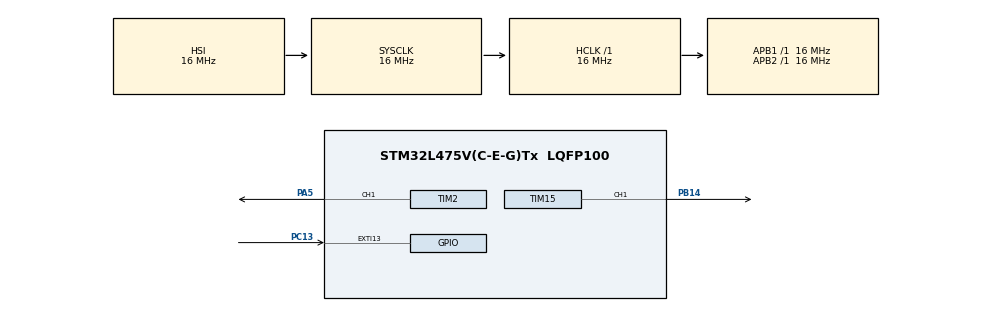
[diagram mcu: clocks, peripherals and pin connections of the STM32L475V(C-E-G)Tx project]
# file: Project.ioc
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Mcu.Family=STM32L4
Mcu.Name=STM32L475V(C-E-G)Tx
Mcu.Package=LQFP100
NVIC.EXTI15_10_IRQn=true\:0\:0\:false\:false\:true\:true\:true
NVIC.PriorityGroup=NVIC_PRIORITYGROUP_4
PA5.Signal=S_TIM2_CH1
PB14.Signal=S_TIM15_CH1
PC13.Signal=GPXTI13
ProjectManager.HeapSize=0x200
ProjectManager.StackSize=0x400
ProjectManager.TargetToolchain=EWARM V8.32
RCC.AHBFreq_Value=16000000
RCC.APB1Freq_Value=16000000
RCC.APB1TimFreq_Value=16000000
RCC.APB2Freq_Value=16000000
RCC.APB2TimFreq_Value=16000000
RCC.CortexFreq_Value=16000000
RCC.HCLKFreq_Value=16000000
RCC.HSE_VALUE=8000000
RCC.HSI_VALUE=16000000
RCC.LSE_VALUE=32768
RCC.MSI_VALUE=4000000
RCC.SYSCLKFreq_VALUE=16000000
RCC.SYSCLKSource=RCC_SYSCLKSOURCE_HSI
RCC.VCOOutputFreq_Value=32000000
SH.S_TIM15_CH1.0=TIM15_CH1,PWM Generation1 CH1
SH.S_TIM2_CH1.0=TIM2_CH1,PWM Generation1 CH1
TIM15.Channel-PWM\ Generation1\ CH1=TIM_CHANNEL_1
TIM15.Period=2000-1
TIM15.Prescaler=160-1
TIM2.Channel-PWM\ Generation1\ CH1=TIM_CHANNEL_1
TIM2.Period=2000-1
TIM2.Prescaler=160-1
VP_TIM15_VS_ClockSourceINT.Mode=Internal
VP_TIM2_VS_ClockSourceINT.Mode=Internal
board=custom

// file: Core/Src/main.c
/* USER CODE BEGIN Header */
/**
  ******************************************************************************
  * @file           : main.c
  * @brief          : Main program body
  ******************************************************************************
  * @attention
  *
  * <h2><center>&copy; Copyright (c) 2021 STMicroelectronics.
  * All rights reserved.</center></h2>
  *
  * This software component is licensed by ST under BSD 3-Clause license,
  * the "License"; You may not use this file except in compliance with the
  * License. You may obtain a copy of the License at:
  *                        opensource.org/licenses/BSD-3-Clause
  *
  ******************************************************************************
  */
/* USER CODE END Header */
#include "main.h"

TIM_HandleTypeDef htim2;
TIM_HandleTypeDef htim15;

/* USER CODE BEGIN PV */

typedef enum
{
  LED_OFF = 0x00,
  LED_ON  = 0x01,
  LED_BLINK_SLOW = 0x02,
  LED_BLINK_FAST = 0x03,
  LED_DIM_SLOW = 0x04,
  LED_DIM_FAST = 0x05,
  LED_STATE_CNT = 0x06
} LEDState;

volatile LEDState curState = LED_OFF;

/* USER CODE END PV */

void SystemClock_Config(void);
static void MX_GPIO_Init(void);
static void MX_TIM2_Init(void);
static void MX_TIM15_Init(void);

/* USER CODE BEGIN 0 */

/*
  User button interrupt handler
*/
void HAL_GPIO_EXTI_Callback(uint16_t GPIO_Pin)
{
  curState++;
  curState %= LED_STATE_CNT;
}

void user_pwm_setvalue(uint16_t value, TIM_HandleTypeDef * htim)
{
    TIM_OC_InitTypeDef sConfigOC;

    sConfigOC.OCMode = TIM_OCMODE_PWM1;
    sConfigOC.Pulse = value;
    sConfigOC.OCPolarity = TIM_OCPOLARITY_HIGH;
    sConfigOC.OCFastMode = TIM_OCFAST_DISABLE;
    HAL_TIM_PWM_ConfigChannel(htim, &sConfigOC, TIM_CHANNEL_1);
    HAL_TIM_PWM_Start(htim, TIM_CHANNEL_1);
}

void EnableGPIOMode()
{
  // Set alternate function mode (0x01) on GPIO A and B
  GPIOA->MODER |= GPIO_MODER_MODE5_0;
  GPIOA->MODER &= ~GPIO_MODER_MODE5_1;
  GPIOB->MODER |= GPIO_MODER_MODE14_0;
  GPIOB->MODER &= ~GPIO_MODER_MODE14_1;
}

void EnableAltFuncMode()
{
  // Set alternate function mode (0x02) on GPIO A and B
  GPIOA->MODER &= ~GPIO_MODER_MODE5_0;
  GPIOA->MODER |= GPIO_MODER_MODE5_1;
  GPIOA->MODER &= ~GPIO_MODER_MODE14_0;
  GPIOA->MODER |= GPIO_MODER_MODE14_1;
}

/* USER CODE END 0 */

int main(void)
{
  /* USER CODE BEGIN 1 */
  int pwmValue = 0;
  int stepping = 100;

  /* USER CODE END 1 */

  /* MCU Configuration--------------------------------------------------------*/

  /* Reset of all peripherals, Initializes the Flash interface and the Systick. */
  HAL_Init();

  /* Configure the system clock */
  SystemClock_Config();

  /* Initialize all configured peripherals */
  MX_GPIO_Init();
  MX_TIM2_Init();
  MX_TIM15_Init();

  /* Infinite loop */
  while (1)
  {

    /* USER CODE BEGIN 3 */
    switch(curState)
    {
      case LED_OFF:
      {
        EnableGPIOMode();
        GPIOA->ODR = ~GPIO_ODR_OD5;
        GPIOB->ODR = ~GPIO_ODR_OD14;
        break;
      }

      case LED_ON:
      {
        EnableGPIOMode();
        GPIOA->ODR |= GPIO_ODR_OD5;  // LED1
        GPIOB->ODR |= GPIO_ODR_OD14; // LED2
        break;
      }

      case LED_BLINK_SLOW:
      {
        EnableGPIOMode();
        GPIOA->ODR = ~GPIO_ODR_OD5;
        GPIOB->ODR = ~GPIO_ODR_OD14;
        HAL_Delay(1000);
        GPIOA->ODR |= GPIO_ODR_OD5;  // LED1
        GPIOB->ODR |= GPIO_ODR_OD14; // LED2
        HAL_Delay(1000);
      }

      case LED_BLINK_FAST:
      {
        EnableGPIOMode();
        GPIOA->ODR = ~GPIO_ODR_OD5;
        GPIOB->ODR = ~GPIO_ODR_OD14;
        HAL_Delay(500);
        GPIOA->ODR |= GPIO_ODR_OD5;  // LED1
        GPIOB->ODR |= GPIO_ODR_OD14; // LED2
        HAL_Delay(500);
      }

      case LED_DIM_SLOW:
      {
        EnableAltFuncMode();

        // Set AFR to use the timers for each LED
        GPIOA->AFR[0] &= ~GPIO_AFRL_AFSEL5_Msk;
        GPIOA->AFR[0] |= GPIO_AFRL_AFSEL5_0;
        GPIOB->AFR[1] &= ~GPIO_AFRH_AFSEL14_Msk;
        GPIOB->AFR[1] |= (GPIO_AFRH_AFSEL14_1 | GPIO_AFRH_AFSEL14_2 | GPIO_AFRH_AFSEL14_3);

        // Run the light sequence
        if (pwmValue ==0) stepping = 100; else if (pwmValue == 2000) stepping = -100;
        pwmValue += stepping;
        user_pwm_setvalue(pwmValue, &htim2);
        user_pwm_setvalue(pwmValue, &htim15);
        break;
      }

      case LED_DIM_FAST:
      {
        EnableAltFuncMode();
      }
    }

    /*if ((GPIOC->IDR & GPIO_IDR_ID13) == 0)
    {
      GPIOA->ODR ^= GPIO_ODR_OD5;  // LED1
      GPIOB->ODR ^= GPIO_ODR_OD14; // LED2
    }*/
  }
  /* USER CODE END 3 */
}

void SystemClock_Config(void)
{
  RCC_OscInitTypeDef RCC_OscInitStruct = {0};
  RCC_ClkInitTypeDef RCC_ClkInitStruct = {0};

  /** Configure the main internal regulator output voltage
  */
  if (HAL_PWREx_ControlVoltageScaling(PWR_REGULATOR_VOLTAGE_SCALE1) != HAL_OK)
  {
    Error_Handler();
  }
  /** Initializes the RCC Oscillators according to the specified parameters
  * in the RCC_OscInitTypeDef structure.
  */
  RCC_OscInitStruct.OscillatorType = RCC_OSCILLATORTYPE_HSI;
  RCC_OscInitStruct.HSIState = RCC_HSI_ON;
  RCC_OscInitStruct.HSICalibrationValue = RCC_HSICALIBRATION_DEFAULT;
  RCC_OscInitStruct.PLL.PLLState = RCC_PLL_NONE;
  if (HAL_RCC_OscConfig(&RCC_OscInitStruct) != HAL_OK)
  {
    Error_Handler();
  }
  /** Initializes the CPU, AHB and APB buses clocks
  */
  RCC_ClkInitStruct.ClockType = RCC_CLOCKTYPE_HCLK|RCC_CLOCKTYPE_SYSCLK
                              |RCC_CLOCKTYPE_PCLK1|RCC_CLOCKTYPE_PCLK2;
  RCC_ClkInitStruct.SYSCLKSource = RCC_SYSCLKSOURCE_HSI;
  RCC_ClkInitStruct.AHBCLKDivider = RCC_SYSCLK_DIV1;
  RCC_ClkInitStruct.APB1CLKDivider = RCC_HCLK_DIV1;
  RCC_ClkInitStruct.APB2CLKDivider = RCC_HCLK_DIV1;

  if (HAL_RCC_ClockConfig(&RCC_ClkInitStruct, FLASH_LATENCY_0) != HAL_OK)
  {
    Error_Handler();
  }
}

static void MX_TIM2_Init(void)
{

  TIM_ClockConfigTypeDef sClockSourceConfig = {0};
  TIM_MasterConfigTypeDef sMasterConfig = {0};
  TIM_OC_InitTypeDef sConfigOC = {0};

  htim2.Instance = TIM2;
  htim2.Init.Prescaler = 160-1;
  htim2.Init.CounterMode = TIM_COUNTERMODE_UP;
  htim2.Init.Period = 2000-1;
  htim2.Init.ClockDivision = TIM_CLOCKDIVISION_DIV1;
  htim2.Init.AutoReloadPreload = TIM_AUTORELOAD_PRELOAD_DISABLE;
  if (HAL_TIM_Base_Init(&htim2) != HAL_OK)
  {
    Error_Handler();
  }
  sClockSourceConfig.ClockSource = TIM_CLOCKSOURCE_INTERNAL;
  if (HAL_TIM_ConfigClockSource(&htim2, &sClockSourceConfig) != HAL_OK)
  {
    Error_Handler();
  }
  if (HAL_TIM_PWM_Init(&htim2) != HAL_OK)
  {
    Error_Handler();
  }
  sMasterConfig.MasterOutputTrigger = TIM_TRGO_RESET;
  sMasterConfig.MasterSlaveMode = TIM_MASTERSLAVEMODE_DISABLE;
  if (HAL_TIMEx_MasterConfigSynchronization(&htim2, &sMasterConfig) != HAL_OK)
  {
    Error_Handler();
  }
  sConfigOC.OCMode = TIM_OCMODE_PWM1;
  sConfigOC.Pulse = 0;
  sConfigOC.OCPolarity = TIM_OCPOLARITY_HIGH;
  sConfigOC.OCFastMode = TIM_OCFAST_DISABLE;
  if (HAL_TIM_PWM_ConfigChannel(&htim2, &sConfigOC, TIM_CHANNEL_1) != HAL_OK)
  {
    Error_Handler();
  }
  HAL_TIM_MspPostInit(&htim2);

}

static void MX_TIM15_Init(void)
{

  TIM_ClockConfigTypeDef sClockSourceConfig = {0};
  TIM_MasterConfigTypeDef sMasterConfig = {0};
  TIM_OC_InitTypeDef sConfigOC = {0};
  TIM_BreakDeadTimeConfigTypeDef sBreakDeadTimeConfig = {0};

  htim15.Instance = TIM15;
  htim15.Init.Prescaler = 160-1;
  htim15.Init.CounterMode = TIM_COUNTERMODE_UP;
  htim15.Init.Period = 2000-1;
  htim15.Init.ClockDivision = TIM_CLOCKDIVISION_DIV1;
  htim15.Init.RepetitionCounter = 0;
  htim15.Init.AutoReloadPreload = TIM_AUTORELOAD_PRELOAD_DISABLE;
  if (HAL_TIM_Base_Init(&htim15) != HAL_OK)
  {
    Error_Handler();
  }
  sClockSourceConfig.ClockSource = TIM_CLOCKSOURCE_INTERNAL;
  if (HAL_TIM_ConfigClockSource(&htim15, &sClockSourceConfig) != HAL_OK)
  {
    Error_Handler();
  }
  if (HAL_TIM_PWM_Init(&htim15) != HAL_OK)
  {
    Error_Handler();
  }
  sMasterConfig.MasterOutputTrigger = TIM_TRGO_RESET;
  sMasterConfig.MasterSlaveMode = TIM_MASTERSLAVEMODE_DISABLE;
  if (HAL_TIMEx_MasterConfigSynchronization(&htim15, &sMasterConfig) != HAL_OK)
  {
    Error_Handler();
  }
  sConfigOC.OCMode = TIM_OCMODE_PWM1;
  sConfigOC.Pulse = 0;
  sConfigOC.OCPolarity = TIM_OCPOLARITY_HIGH;
  sConfigOC.OCNPolarity = TIM_OCNPOLARITY_HIGH;
  sConfigOC.OCFastMode = TIM_OCFAST_DISABLE;
  sConfigOC.OCIdleState = TIM_OCIDLESTATE_RESET;
  sConfigOC.OCNIdleState = TIM_OCNIDLESTATE_RESET;
  if (HAL_TIM_PWM_ConfigChannel(&htim15, &sConfigOC, TIM_CHANNEL_1) != HAL_OK)
  {
    Error_Handler();
  }
  sBreakDeadTimeConfig.OffStateRunMode = TIM_OSSR_DISABLE;
  sBreakDeadTimeConfig.OffStateIDLEMode = TIM_OSSI_DISABLE;
  sBreakDeadTimeConfig.LockLevel = TIM_LOCKLEVEL_OFF;
  sBreakDeadTimeConfig.DeadTime = 0;
  sBreakDeadTimeConfig.BreakState = TIM_BREAK_DISABLE;
  sBreakDeadTimeConfig.BreakPolarity = TIM_BREAKPOLARITY_HIGH;
  sBreakDeadTimeConfig.AutomaticOutput = TIM_AUTOMATICOUTPUT_DISABLE;
  if (HAL_TIMEx_ConfigBreakDeadTime(&htim15, &sBreakDeadTimeConfig) != HAL_OK)
  {
    Error_Handler();
  }
  HAL_TIM_MspPostInit(&htim15);

}

static void MX_GPIO_Init(void)
{
  GPIO_InitTypeDef GPIO_InitStruct = {0};

  /* GPIO Ports Clock Enable */
  __HAL_RCC_GPIOC_CLK_ENABLE();
  __HAL_RCC_GPIOA_CLK_ENABLE();
  __HAL_RCC_GPIOB_CLK_ENABLE();

  /*Configure GPIO pin : PC13 */
  GPIO_InitStruct.Pin = GPIO_PIN_13;
  GPIO_InitStruct.Mode = GPIO_MODE_IT_RISING;
  GPIO_InitStruct.Pull = GPIO_NOPULL;
  HAL_GPIO_Init(GPIOC, &GPIO_InitStruct);

  /* EXTI interrupt init*/
  HAL_NVIC_SetPriority(EXTI15_10_IRQn, 0, 0);
  HAL_NVIC_EnableIRQ(EXTI15_10_IRQn);

}

void Error_Handler(void)
{
  __disable_irq();
  while (1)
  {
  }
}

/************************ (C) COPYRIGHT STMicroelectronics *****END OF FILE****/
